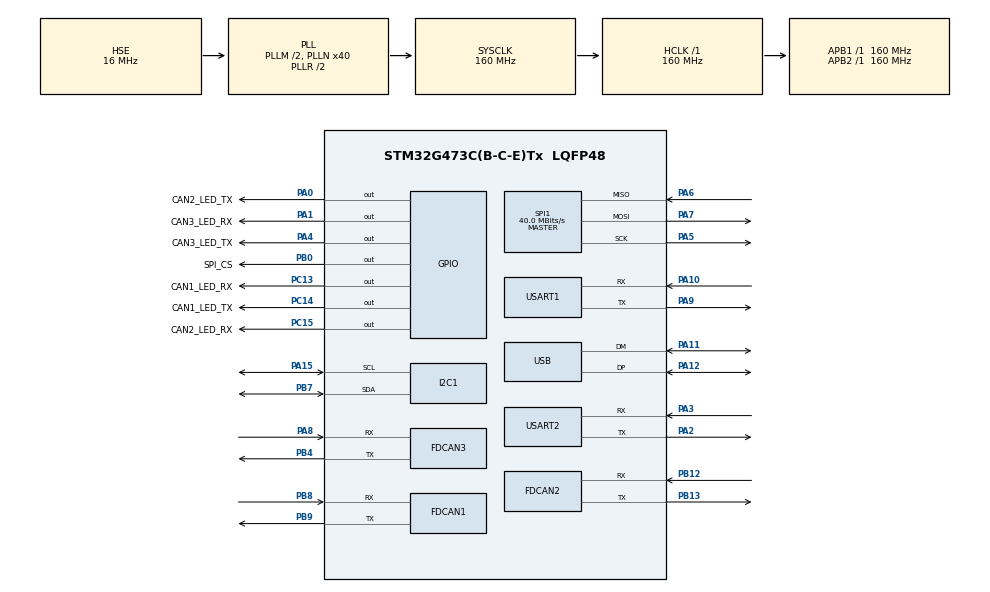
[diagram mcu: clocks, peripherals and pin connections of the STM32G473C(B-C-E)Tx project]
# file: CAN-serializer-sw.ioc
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FDCAN1.CalculateBaudRateData=5000000
FDCAN1.CalculateBaudRateNominal=500000
FDCAN1.CalculateTimeBitData=200
FDCAN1.CalculateTimeBitNominal=2000
FDCAN1.CalculateTimeQuantumData=12.5
FDCAN1.CalculateTimeQuantumNominal=12.5
FDCAN1.DataPrescaler=1
FDCAN1.DataSyncJumpWidth=4
FDCAN1.DataTimeSeg1=11
FDCAN1.DataTimeSeg2=4
FDCAN1.FrameFormat=FDCAN_FRAME_FD_BRS
FDCAN1.NominalPrescaler=1
FDCAN1.NominalSyncJumpWidth=32
FDCAN1.NominalTimeSeg1=127
FDCAN1.NominalTimeSeg2=32
FDCAN2.CalculateBaudRateData=5000000
FDCAN2.CalculateBaudRateNominal=500000
FDCAN2.CalculateTimeBitData=200
FDCAN2.CalculateTimeBitNominal=2000
FDCAN2.CalculateTimeQuantumData=12.5
FDCAN2.CalculateTimeQuantumNominal=12.5
FDCAN2.DataPrescaler=1
FDCAN2.DataSyncJumpWidth=4
FDCAN2.DataTimeSeg1=11
FDCAN2.DataTimeSeg2=4
FDCAN2.FrameFormat=FDCAN_FRAME_FD_BRS
FDCAN2.NominalPrescaler=1
FDCAN2.NominalSyncJumpWidth=32
FDCAN2.NominalTimeSeg1=127
FDCAN2.NominalTimeSeg2=32
FDCAN3.CalculateBaudRateData=5000000
FDCAN3.CalculateBaudRateNominal=500000
FDCAN3.CalculateTimeBitData=200
FDCAN3.CalculateTimeBitNominal=2000
FDCAN3.CalculateTimeQuantumData=12.5
FDCAN3.CalculateTimeQuantumNominal=12.5
FDCAN3.DataPrescaler=1
FDCAN3.DataSyncJumpWidth=4
FDCAN3.DataTimeSeg1=11
FDCAN3.DataTimeSeg2=4
FDCAN3.FrameFormat=FDCAN_FRAME_FD_BRS
FDCAN3.NominalPrescaler=1
FDCAN3.NominalSyncJumpWidth=32
FDCAN3.NominalTimeSeg1=127
FDCAN3.NominalTimeSeg2=32
I2C1.Timing=0x30D29DE4
Mcu.Family=STM32G4
Mcu.Name=STM32G473C(B-C-E)Tx
Mcu.Package=LQFP48
NVIC.FDCAN1_IT0_IRQn=true\:1\:0\:false\:false\:true\:true\:true\:true
NVIC.FDCAN2_IT0_IRQn=true\:1\:0\:false\:false\:true\:true\:true\:true
NVIC.FDCAN3_IT0_IRQn=true\:1\:0\:false\:false\:true\:true\:true\:true
NVIC.PriorityGroup=NVIC_PRIORITYGROUP_4
NVIC.USB_LP_IRQn=true\:2\:0\:false\:false\:true\:true\:true\:true
PA0.GPIO_Label=CAN2_LED_TX
PA0.Signal=GPIO_Output
PA1.GPIO_Label=CAN3_LED_RX
PA1.Signal=GPIO_Output
PA10.Mode=Asynchronous
PA10.Signal=USART1_RX
PA11.Mode=Device
PA11.Signal=USB_DM
PA12.Mode=Device
PA12.Signal=USB_DP
PA13.Mode=Trace_Asynchronous_SW
PA13.Signal=SYS_JTMS-SWDIO
PA14.Mode=Trace_Asynchronous_SW
PA14.Signal=SYS_JTCK-SWCLK
PA15.Mode=I2C
PA15.Signal=I2C1_SCL
PA2.Mode=Asynchronous
PA2.Signal=USART2_TX
PA3.Mode=Asynchronous
PA3.Signal=USART2_RX
PA4.GPIO_Label=CAN3_LED_TX
PA4.Signal=GPIO_Output
PA5.Mode=Full_Duplex_Master
PA5.Signal=SPI1_SCK
PA6.Mode=Full_Duplex_Master
PA6.Signal=SPI1_MISO
PA7.Mode=Full_Duplex_Master
PA7.Signal=SPI1_MOSI
PA8.Mode=FDCAN_Activate
PA8.Signal=FDCAN3_RX
PA9.Mode=Asynchronous
PA9.Signal=USART1_TX
PB0.GPIO_Label=SPI_CS
PB0.Signal=GPIO_Output
PB12.Mode=FDCAN_Activate
PB12.Signal=FDCAN2_RX
PB13.Mode=FDCAN_Activate
PB13.Signal=FDCAN2_TX
PB3.Mode=Trace_Asynchronous_SW
PB3.Signal=SYS_JTDO-SWO
PB4.Mode=FDCAN_Activate
PB4.Signal=FDCAN3_TX
PB7.Mode=I2C
PB7.Signal=I2C1_SDA
PB8-BOOT0.Mode=FDCAN_Activate
PB8-BOOT0.Signal=FDCAN1_RX
PB9.Mode=FDCAN_Activate
PB9.Signal=FDCAN1_TX
PC13.GPIO_Label=CAN1_LED_RX
PC13.Signal=GPIO_Output
PC14-OSC32_IN.GPIO_Label=CAN1_LED_TX
PC14-OSC32_IN.Signal=GPIO_Output
PC15-OSC32_OUT.GPIO_Label=CAN2_LED_RX
PC15-OSC32_OUT.Signal=GPIO_Output
PF0-OSC_IN.Mode=HSE-External-Oscillator
PF0-OSC_IN.Signal=RCC_OSC_IN
PF1-OSC_OUT.Mode=HSE-External-Oscillator
PF1-OSC_OUT.Signal=RCC_OSC_OUT
ProjectManager.HeapSize=0x200
ProjectManager.StackSize=0x400
ProjectManager.TargetToolchain=Makefile
RCC.ADC12Freq_Value=160000000
RCC.ADC345Freq_Value=160000000
RCC.AHBFreq_Value=160000000
RCC.APB1Freq_Value=160000000
RCC.APB1TimFreq_Value=160000000
RCC.APB2Freq_Value=160000000
RCC.APB2TimFreq_Value=160000000
RCC.CK48CLockSelection=RCC_USBCLKSOURCE_HSI48
RCC.CortexFreq_Value=160000000
RCC.EXTERNAL_CLOCK_VALUE=12288000
RCC.FDCANCLockSelection=RCC_FDCANCLKSOURCE_PLL
RCC.HCLKFreq_Value=160000000
RCC.HSE_VALUE=16000000
RCC.HSI48_VALUE=48000000
RCC.HSICalibrationValue=16
RCC.HSI_VALUE=16000000
RCC.LSE_VALUE=32768
RCC.PLLM=RCC_PLLM_DIV2
RCC.PLLN=40
RCC.PLLQ=RCC_PLLQ_DIV4
RCC.PLLSourceVirtual=RCC_PLLSOURCE_HSE
RCC.SYSCLKFreq_VALUE=160000000
RCC.SYSCLKSource=RCC_SYSCLKSOURCE_PLLCLK
RCC.USBFreq_Value=48000000
RCC.VCOOutputFreq_Value=320000000
SPI1.BaudRatePrescaler=SPI_BAUDRATEPRESCALER_4
SPI1.CalculateBaudRate=40.0 MBits/s
SPI1.Direction=SPI_DIRECTION_2LINES
SPI1.Mode=SPI_MODE_MASTER
SPI1.NSSPMode=SPI_NSS_PULSE_ENABLE
SPI1.VirtualType=VM_MASTER
USART1.VirtualMode-Asynchronous=VM_ASYNC
USART2.VirtualMode-Asynchronous=VM_ASYNC
VP_SYS_VS_DBSignals.Mode=DisableDeadBatterySignals
board=custom

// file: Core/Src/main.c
/* USER CODE BEGIN Header */
/**
  ******************************************************************************
  * @file           : main.c
  * @brief          : Main program body
  ******************************************************************************
  * @attention
  *
  * Copyright (c) 2026 STMicroelectronics.
  * All rights reserved.
  *
  * This software is licensed under terms that can be found in the LICENSE file
  * in the root directory of this software component.
  * If no LICENSE file comes with this software, it is provided AS-IS.
  *
  ******************************************************************************
  */
/* USER CODE END Header */
#include "main.h"
#include "fdcan.h"
#include "i2c.h"
#include "spi.h"
#include "usart.h"
#include "usb.h"
#include "gpio.h"

/* USER CODE BEGIN Includes */
#include "serializer.h"
/* USER CODE END Includes */

void SystemClock_Config(void);

int main(void) {

    /* MCU Configuration--------------------------------------------------------*/

    /* Reset of all peripherals, Initializes the Flash interface and the Systick. */
    HAL_Init();

    /* Configure the system clock */
    SystemClock_Config();

    /* Initialize all configured peripherals */
    MX_GPIO_Init();
    MX_FDCAN1_Init();
    MX_FDCAN2_Init();
    MX_FDCAN3_Init();
    MX_I2C1_Init();
    MX_SPI1_Init();
    MX_USART1_UART_Init();
    MX_USB_PCD_Init();
    MX_USART2_UART_Init();
    /* USER CODE BEGIN 2 */
    serializer_init();
    /* USER CODE END 2 */

    /* Infinite loop */
    while (1) {

        /* USER CODE BEGIN 3 */
        serializer_loop();
    }
    /* USER CODE END 3 */
}

void SystemClock_Config(void) {
    RCC_OscInitTypeDef RCC_OscInitStruct = { 0 };
    RCC_ClkInitTypeDef RCC_ClkInitStruct = { 0 };

    /** Configure the main internal regulator output voltage
  */
    HAL_PWREx_ControlVoltageScaling(PWR_REGULATOR_VOLTAGE_SCALE1_BOOST);

    /** Initializes the RCC Oscillators according to the specified parameters
  * in the RCC_OscInitTypeDef structure.
  */
    RCC_OscInitStruct.OscillatorType = RCC_OSCILLATORTYPE_HSI48 | RCC_OSCILLATORTYPE_HSE;
    RCC_OscInitStruct.HSEState = RCC_HSE_ON;
    RCC_OscInitStruct.HSI48State = RCC_HSI48_ON;
    RCC_OscInitStruct.PLL.PLLState = RCC_PLL_ON;
    RCC_OscInitStruct.PLL.PLLSource = RCC_PLLSOURCE_HSE;
    RCC_OscInitStruct.PLL.PLLM = RCC_PLLM_DIV2;
    RCC_OscInitStruct.PLL.PLLN = 40;
    RCC_OscInitStruct.PLL.PLLP = RCC_PLLP_DIV2;
    RCC_OscInitStruct.PLL.PLLQ = RCC_PLLQ_DIV4;
    RCC_OscInitStruct.PLL.PLLR = RCC_PLLR_DIV2;
    if (HAL_RCC_OscConfig(&RCC_OscInitStruct) != HAL_OK) {
        Error_Handler();
    }

    /** Initializes the CPU, AHB and APB buses clocks
  */
    RCC_ClkInitStruct.ClockType = RCC_CLOCKTYPE_HCLK | RCC_CLOCKTYPE_SYSCLK | RCC_CLOCKTYPE_PCLK1 | RCC_CLOCKTYPE_PCLK2;
    RCC_ClkInitStruct.SYSCLKSource = RCC_SYSCLKSOURCE_PLLCLK;
    RCC_ClkInitStruct.AHBCLKDivider = RCC_SYSCLK_DIV1;
    RCC_ClkInitStruct.APB1CLKDivider = RCC_HCLK_DIV1;
    RCC_ClkInitStruct.APB2CLKDivider = RCC_HCLK_DIV1;

    if (HAL_RCC_ClockConfig(&RCC_ClkInitStruct, FLASH_LATENCY_4) != HAL_OK) {
        Error_Handler();
    }
}

void Error_Handler(void) {
    __disable_irq();
    while (1) {
    }
}
